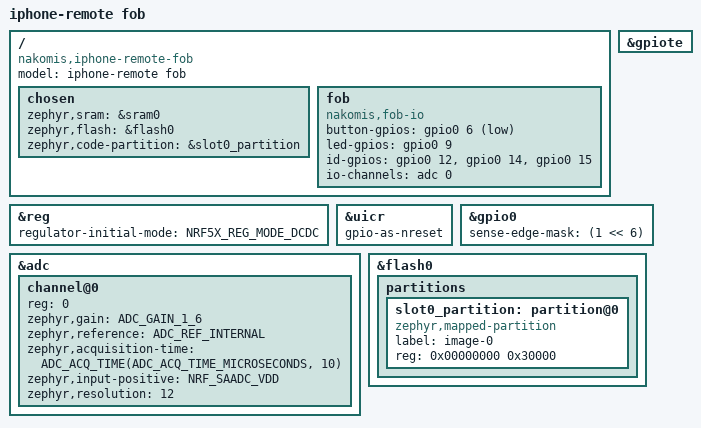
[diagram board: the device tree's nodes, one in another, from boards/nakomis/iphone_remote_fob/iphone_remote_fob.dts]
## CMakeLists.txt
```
cmake_minimum_required(VERSION 3.20.0)

# The fob's own board (boards/nakomis/iphone_remote_fob) and devicetree binding.
list(APPEND BOARD_ROOT ${CMAKE_CURRENT_SOURCE_DIR})
list(APPEND DTS_ROOT ${CMAKE_CURRENT_SOURCE_DIR})

find_package(Zephyr REQUIRED HINTS $ENV{ZEPHYR_BASE})
project(iphone_remote_fob)

target_sources(app PRIVATE src/main.c src/protocol.c)
```

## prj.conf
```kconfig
# Bluetooth: broadcaster (the press) and observer (the ack). No connections, no GATT.
CONFIG_BT=y
CONFIG_BT_BROADCASTER=y
CONFIG_BT_OBSERVER=y
CONFIG_BT_PERIPHERAL=n
CONFIG_BT_CENTRAL=n
CONFIG_BT_EXT_ADV=n
CONFIG_BT_DEVICE_NAME="iphone-remote"

CONFIG_GPIO=y
CONFIG_ADC=y
CONFIG_ENTROPY_GENERATOR=y

# Small: the nRF52810 has 192 KB flash and 24 KB RAM.
CONFIG_LOG=n
CONFIG_ASSERT=n
CONFIG_MAIN_STACK_SIZE=1536
CONFIG_SYSTEM_WORKQUEUE_STACK_SIZE=1024
CONFIG_SIZE_OPTIMIZATIONS=y
```

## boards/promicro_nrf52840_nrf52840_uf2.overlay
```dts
/* Development on the Pro Micro nRF52840 (UF2 bootloader: double-tap reset, copy
 * build/fob/zephyr/zephyr.uf2 to the drive). Wire a button from P0.17 to GND; the ID
 * jumpers are P0.20, P0.22 and P0.24 to GND (all open: fob 0). The LED is the board's own. */
#include <zephyr/dt-bindings/adc/nrf-saadc.h>

/ {
	fob {
		compatible = "nakomis,fob-io";
		button-gpios = <&gpio0 17 (GPIO_ACTIVE_LOW | GPIO_PULL_UP)>;
		led-gpios = <&gpio0 15 GPIO_ACTIVE_HIGH>;
		id-gpios = <&gpio0 20 0>, <&gpio0 22 0>, <&gpio0 24 0>;
		io-channels = <&adc 0>;
	};
};

&gpio0 {
	sense-edge-mask = <(1 << 17)>;
};

&adc {
	#address-cells = <1>;
	#size-cells = <0>;

	channel@0 {
		reg = <0>;
		zephyr,gain = "ADC_GAIN_1_6";
		zephyr,reference = "ADC_REF_INTERNAL";
		zephyr,acquisition-time = <ADC_ACQ_TIME(ADC_ACQ_TIME_MICROSECONDS, 10)>;
		zephyr,input-positive = <NRF_SAADC_VDD>;
		zephyr,resolution = <12>;
	};
};
```

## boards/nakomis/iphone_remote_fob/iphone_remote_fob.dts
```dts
/* The iphone-remote fob (hardware/fob, IREM-3/4): nRF52810-QCAA on a CR2032, DC/DC on,
 * no 32 kHz crystal. Pins from hardware/fob/board/fob_board.py. */
/dts-v1/;
#include <nordic/nrf52810_qfaa.dtsi>
#include <zephyr/dt-bindings/adc/nrf-saadc.h>

/ {
	model = "iphone-remote fob";
	compatible = "nakomis,iphone-remote-fob";

	chosen {
		zephyr,sram = &sram0;
		zephyr,flash = &flash0;
		zephyr,code-partition = &slot0_partition;
	};

	/* What the application drives (src/main.c). */
	fob {
		compatible = "nakomis,fob-io";
		/* SW1 to GND, with R2, an external 1 M pull-up. */
		button-gpios = <&gpio0 6 GPIO_ACTIVE_LOW>;
		/* D1, red, high-active through R1 (470 R). */
		led-gpios = <&gpio0 9 GPIO_ACTIVE_HIGH>;
		/* JP1..JP3 to GND: bit 0, 1, 2. The internal pull-ups are on only while they're read. */
		id-gpios = <&gpio0 12 0>, <&gpio0 14 0>, <&gpio0 15 0>;
		io-channels = <&adc 0>;
	};
};

&reg {
	regulator-initial-mode = <NRF5X_REG_MODE_DCDC>;
};

&uicr {
	gpio-as-nreset;
};

&gpiote {
	status = "okay";
};

/* The button wakes the chip with the port's SENSE, not a GPIOTE IN channel (which costs
 * current while waiting). */
&gpio0 {
	status = "okay";
	sense-edge-mask = <(1 << 6)>;
};

&adc {
	status = "okay";
	#address-cells = <1>;
	#size-cells = <0>;

	/* VDD, the cell, through the SAADC's own divider. */
	channel@0 {
		reg = <0>;
		zephyr,gain = "ADC_GAIN_1_6";
		zephyr,reference = "ADC_REF_INTERNAL";
		zephyr,acquisition-time = <ADC_ACQ_TIME(ADC_ACQ_TIME_MICROSECONDS, 10)>;
		zephyr,input-positive = <NRF_SAADC_VDD>;
		zephyr,resolution = <12>;
	};
};

&flash0 {
	partitions {
		ranges;
		#address-cells = <1>;
		#size-cells = <1>;

		/* No bootloader: the whole 192 KB is the application, flashed over SWD. */
		slot0_partition: partition@0 {
			compatible = "zephyr,mapped-partition";
			label = "image-0";
			reg = <0x00000000 0x30000>;
		};
	};
};
```

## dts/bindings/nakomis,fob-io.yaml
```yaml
description: The iphone-remote fob's button, LED, ID jumpers and VDD channel.

compatible: "nakomis,fob-io"

properties:
  button-gpios:
    type: phandle-array
    required: true
    description: The press button, active low.
  led-gpios:
    type: phandle-array
    required: true
    description: The ack LED.
  id-gpios:
    type: phandle-array
    required: true
    description: The three fob-ID jumpers to GND, bit 0 first. Read with the internal pull-ups.
  io-channels:
    type: phandle-array
    required: true
    description: The ADC channel that measures VDD.
```

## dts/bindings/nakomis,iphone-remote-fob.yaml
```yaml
description: The iphone-remote fob's button, LED, ID jumpers and VDD channel.

compatible: "nakomis,iphone-remote-fob"

properties:
  button-gpios:
    type: phandle-array
    required: true
    description: The press button, active low.
  led-gpios:
    type: phandle-array
    required: true
    description: The ack LED.
  id-gpios:
    type: phandle-array
    required: true
    description: The three fob-ID jumpers to GND, bit 0 first. Read with the internal pull-ups.
  io-channels:
    type: phandle-array
    required: true
    description: The ADC channel that measures VDD.
```

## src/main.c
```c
/* iphone-remote fob firmware (IREM-6): one press, one advert burst, one ack.
 *
 * Idle: System ON sleep, waiting on the button's SENSE. A press reads the fob ID and VDD,
 * advertises the press for up to 300 ms and scans for the phone's ack for up to 2 s. A matching
 * ack stops both and flashes the LED once; no ack gives two short flashes. Protocol:
 * docs/protocol.md (IREM-2); behaviour: the design doc's §7. */
#include <zephyr/bluetooth/bluetooth.h>
#include <zephyr/bluetooth/gap.h>
#include <zephyr/drivers/adc.h>
#include <zephyr/drivers/gpio.h>
#include <zephyr/kernel.h>
#include <zephyr/random/random.h>
#include <zephyr/sys/atomic.h>
#include <zephyr/sys/util.h>

#include "protocol.h"

#define FOB_NODE DT_PATH(fob)

/* Timing, docs/protocol.md §5. */
#define ADV_INTERVAL 0x20		/* 20 ms, in 0.625 ms units */
#define SCAN_INTERVAL 0x60		/* 60 ms */
#define SCAN_WINDOW 0x30		/* 30 ms: 50% duty */
#define BURST_MS 300
#define LISTEN_MS 2000
#define LISTEN_LOW_MS 1000		/* a tired cell listens for less... */
#define LOW_MV 2200			/* ...below this, and skips the LED */
#define RELEASE_MS 30			/* the button counts as released after this long quiet */
#define ACK_FLASH_MS 50
#define MISS_FLASH_MS 15
#define MISS_GAP_MS 120
#define FAULT_FLASH_MS 100		/* the radio refused to start: three of these */

static const struct gpio_dt_spec button = GPIO_DT_SPEC_GET(FOB_NODE, button_gpios);
static const struct gpio_dt_spec led = GPIO_DT_SPEC_GET(FOB_NODE, led_gpios);
static const struct gpio_dt_spec id_pins[3] = {
	GPIO_DT_SPEC_GET_BY_IDX(FOB_NODE, id_gpios, 0),
	GPIO_DT_SPEC_GET_BY_IDX(FOB_NODE, id_gpios, 1),
	GPIO_DT_SPEC_GET_BY_IDX(FOB_NODE, id_gpios, 2),
};
static const struct adc_dt_spec vdd_channel = ADC_DT_SPEC_GET(FOB_NODE);

/* Everything below runs on this queue, so the press state needs no lock; the scan callback
 * (the Bluetooth RX thread) only reads it to match an ack, then hands over to the queue. */
K_THREAD_STACK_DEFINE(fob_stack, 1536);
static struct k_work_q fob_q;

static struct {
	uint16_t counter;
	uint8_t fob_id;
	bool low;
} press;
/* Set while a press is waiting for its ack (the value of press.counter, plus 1, so 0 = none). */
static atomic_t listening_for;
/* The listening_for value an ack was matched against, so a late ack for an earlier press can't
 * end a newer one. */
static atomic_t acked_for;

/* The button is down. Set by the edge ISR, cleared by release_timer (also interrupt context), so
 * nothing on the work queue can hold up a release. */
static volatile bool held;

static uint8_t mfg[FOB_MFG_LEN];
static const struct bt_data ad[] = {
	BT_DATA(BT_DATA_UUID128_ALL, fob_press_uuid, 16),
	BT_DATA(BT_DATA_MANUFACTURER_DATA, mfg, sizeof(mfg)),
};

static void press_work_fn(struct k_work *w);
static void burst_end_fn(struct k_work *w);
static void listen_end_fn(struct k_work *w);
static void acked_fn(struct k_work *w);
static void led_step_fn(struct k_work *w);
static void release_fn(struct k_timer *t);
static K_WORK_DEFINE(press_work, press_work_fn);
static K_WORK_DEFINE(acked_work, acked_fn);
static K_WORK_DELAYABLE_DEFINE(burst_end, burst_end_fn);
static K_WORK_DELAYABLE_DEFINE(listen_end, listen_end_fn);
static K_WORK_DELAYABLE_DEFINE(led_step, led_step_fn);
static K_TIMER_DEFINE(release_timer, release_fn, NULL);

static uint8_t read_fob_id(void)
{
	int v[3];

	for (int i = 0; i < 3; i++) {
		gpio_pin_configure_dt(&id_pins[i], GPIO_INPUT | GPIO_PULL_UP);
	}
	k_busy_wait(20);
	for (int i = 0; i < 3; i++) {
		v[i] = gpio_pin_get_raw(id_pins[i].port, id_pins[i].pin);
		gpio_pin_configure_dt(&id_pins[i], GPIO_DISCONNECTED);
	}
	return fob_id_from_pins(v[0], v[1], v[2]);
}

/* VDD in mV, or 0 if it couldn't be read. */
static int read_vdd_mv(void)
{
	int16_t raw;
	struct adc_sequence seq = {.buffer = &raw, .buffer_size = sizeof(raw)};

	if (adc_sequence_init_dt(&vdd_channel, &seq) || adc_read_dt(&vdd_channel, &seq)) {
		return 0;
	}
	int32_t mv = raw;

	return adc_raw_to_millivolts_dt(&vdd_channel, &mv) ? 0 : mv;
}

/* LED flashes run on the system work queue, without blocking, so a flash never delays a press.
 * A new pattern replaces one still running. */
static struct {
	int steps;	/* LED changes still to make: on, off, on, off... */
	int on_ms, gap_ms;
} blink;

static void led_step_fn(struct k_work *w)
{
	if (blink.steps <= 0) {
		gpio_pin_set_dt(&led, 0);
		return;
	}
	bool on = blink.steps % 2 == 0;

	gpio_pin_set_dt(&led, on);
	blink.steps--;
	k_work_reschedule(&led_step, K_MSEC(on ? blink.on_ms : blink.gap_ms));
}

static void flash(int times, int on_ms, int gap_ms)
{
	k_work_cancel_delayable(&led_step);
	blink.steps = times * 2;
	blink.on_ms = on_ms;
	blink.gap_ms = gap_ms;
	k_work_reschedule(&led_step, K_NO_WAIT);
}

static void stop_radio(void)
{
	bt_le_adv_stop();
	bt_le_scan_stop();
}

static bool ad_has_ack(struct bt_data *data, void *user)
{
	bool *found = user;

	if ((data->type == BT_DATA_UUID128_ALL || data->type == BT_DATA_UUID128_SOME) &&
	    fob_list_has_ack(data->data, data->data_len, press.fob_id, press.counter)) {
		*found = true;
		return false;
	}
	return true;
}

static void scanned(const bt_addr_le_t *addr, int8_t rssi, uint8_t type, struct net_buf_simple *buf)
{
	bool found = false;
	atomic_val_t want = atomic_get(&listening_for);

	if (want == 0 || want != press.counter + 1) {
		return;
	}
	bt_data_parse(buf, ad_has_ack, &found);
	if (found) {
		atomic_set(&acked_for, want);
		k_work_submit_to_queue(&fob_q, &acked_work);
	}
}

static void press_work_fn(struct k_work *w)
{
	/* Stop a press still listening (a re-press within 2 s) before measuring, so VDD is read
	 * without the radio's load on the cell. */
	atomic_set(&listening_for, 0);
	stop_radio();
	k_msleep(2);
	int mv = read_vdd_mv();

	press.counter++;
	press.fob_id = read_fob_id();
	press.low = mv > 0 && mv < LOW_MV;
	fob_press_mfg(mfg, press.fob_id, press.counter, fob_battery_byte(mv));
	atomic_set(&listening_for, press.counter + 1);

	/* Non-connectable, from the chip's random static address (docs/protocol.md §2). */
	static const struct bt_le_adv_param adv =
		BT_LE_ADV_PARAM_INIT(BT_LE_ADV_OPT_USE_IDENTITY, ADV_INTERVAL, ADV_INTERVAL, NULL);
	static const struct bt_le_scan_param scan = {
		.type = BT_LE_SCAN_TYPE_PASSIVE,
		.interval = SCAN_INTERVAL,
		.window = SCAN_WINDOW,
	};

	if (bt_le_adv_start(&adv, ad, ARRAY_SIZE(ad), NULL, 0) || bt_le_scan_start(&scan, scanned)) {
		/* Not the same as "the phone didn't hear": three long flashes. */
		atomic_set(&listening_for, 0);
		stop_radio();
		flash(3, FAULT_FLASH_MS, FAULT_FLASH_MS);
		return;
	}
	k_work_reschedule_for_queue(&fob_q, &burst_end, K_MSEC(BURST_MS));
	k_work_reschedule_for_queue(&fob_q, &listen_end, K_MSEC(press.low ? LISTEN_LOW_MS : LISTEN_MS));
}

static void burst_end_fn(struct k_work *w)
{
	bt_le_adv_stop();
}

static void listen_end_fn(struct k_work *w)
{
	if (atomic_set(&listening_for, 0) == 0) {
		return;
	}
	stop_radio();
	if (!press.low) {
		flash(2, MISS_FLASH_MS, MISS_GAP_MS);	/* "the phone didn't hear" */
	}
}

static void acked_fn(struct k_work *w)
{
	if (!atomic_cas(&listening_for, atomic_get(&acked_for), 0)) {
		return;	/* a second ack advert for the same press, or one for an earlier press */
	}
	stop_radio();
	k_work_cancel_delayable(&burst_end);
	k_work_cancel_delayable(&listen_end);
	if (!press.low) {
		flash(1, ACK_FLASH_MS, 0);
	}
}

/* The first edge of a press acts at once; the release counts once the pin has been quiet and
 * high for RELEASE_MS, so contact bounce on either edge never makes a second press. Both run in
 * interrupt context at the same priority, so neither interrupts the other. */
static void release_fn(struct k_timer *t)
{
	if (gpio_pin_get_dt(&button) == 0) {
		held = false;
	}
}

static void button_edge(const struct device *dev, struct gpio_callback *cb, uint32_t pins)
{
	if (!held && gpio_pin_get_dt(&button) == 1) {
		held = true;
		k_work_submit_to_queue(&fob_q, &press_work);
	}
	k_timer_start(&release_timer, K_MSEC(RELEASE_MS), K_NO_WAIT);
}

static struct gpio_callback button_cb;

int main(void)
{
	k_work_queue_start(&fob_q, fob_stack, K_THREAD_STACK_SIZEOF(fob_stack), K_PRIO_PREEMPT(5), NULL);

	gpio_pin_configure_dt(&led, GPIO_OUTPUT_INACTIVE);
	for (int i = 0; i < 3; i++) {
		gpio_pin_configure_dt(&id_pins[i], GPIO_DISCONNECTED);
	}
	adc_channel_setup_dt(&vdd_channel);

	if (bt_enable(NULL)) {
		flash(5, 200, 200);	/* can't start the radio: nothing else will work */
		return 0;
	}
	/* A fresh cell must not repeat the counter the phone saw last (docs/protocol.md §2). */
	sys_rand_get(&press.counter, sizeof(press.counter));

	gpio_pin_configure_dt(&button, GPIO_INPUT);
	gpio_init_callback(&button_cb, button_edge, BIT(button.pin));
	gpio_add_callback_dt(&button, &button_cb);
	gpio_pin_interrupt_configure_dt(&button, GPIO_INT_EDGE_BOTH);

	flash(1, 20, 0);	/* alive */
	return 0;
}
```

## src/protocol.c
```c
#include "protocol.h"

#include <string.h>

/* 3B89DBAA-2669-4548-9D04-6876798D0903, reversed. */
const uint8_t fob_press_uuid[16] = {
	0x03, 0x09, 0x8D, 0x79, 0x76, 0x68, 0x04, 0x9D,
	0x48, 0x45, 0x69, 0x26, 0xAA, 0xDB, 0x89, 0x3B,
};

/* The ack prefix 6FDAD356-8165-4FDB-A4F2-B25C2B, reversed: on-air bytes 3..15. */
static const uint8_t ack_prefix_on_air[13] = {
	0x2B, 0x5C, 0xB2, 0xF2, 0xA4, 0xDB, 0x4F, 0x65, 0x81, 0x56, 0xD3, 0xDA, 0x6F,
};

uint8_t fob_battery_byte(int vdd_mv)
{
	if (vdd_mv <= 0) {
		return 0;
	}
	int units = (vdd_mv + 10) / 20;

	return units < 1 ? 1 : units > 255 ? 255 : (uint8_t)units;
}

void fob_press_mfg(uint8_t out[FOB_MFG_LEN], uint8_t fob_id, uint16_t counter, uint8_t battery)
{
	out[0] = FOB_COMPANY_ID & 0xFF;
	out[1] = FOB_COMPANY_ID >> 8;
	out[2] = FOB_PROTOCOL_VERSION;
	out[3] = fob_id;
	out[4] = counter & 0xFF;
	out[5] = counter >> 8;
	out[6] = battery;
}

bool fob_is_ack(const uint8_t *uuid, size_t len, uint8_t fob_id, uint16_t counter)
{
	return len == 16 && uuid[0] == (counter & 0xFF) && uuid[1] == (counter >> 8) &&
	       uuid[2] == fob_id && memcmp(&uuid[3], ack_prefix_on_air, sizeof(ack_prefix_on_air)) == 0;
}

bool fob_list_has_ack(const uint8_t *data, size_t len, uint8_t fob_id, uint16_t counter)
{
	for (size_t i = 0; i + 16 <= len; i += 16) {
		if (fob_is_ack(&data[i], 16, fob_id, counter)) {
			return true;
		}
	}
	return false;
}

uint8_t fob_id_from_pins(int bit0, int bit1, int bit2)
{
	return (uint8_t)((bit0 ? 0 : 1) | (bit1 ? 0 : 2) | (bit2 ? 0 : 4));
}
```

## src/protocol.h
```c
/* The iphone-remote over-the-air protocol, version 1 (docs/protocol.md, IREM-2).
 * Pure functions, no Zephyr: unit tested on the host (tests/). */
#pragma once

#include <stdbool.h>
#include <stddef.h>
#include <stdint.h>

#define FOB_PROTOCOL_VERSION 0x01
#define FOB_COMPANY_ID 0xFFFF
#define FOB_MAX_ID 7

/* Manufacturer data: company ID (2, little-endian) + version, fob_id, counter (2), battery. */
#define FOB_MFG_LEN 7

/* The press UUID 3B89DBAA-2669-4548-9D04-6876798D0903, on-air order (least significant first). */
extern const uint8_t fob_press_uuid[16];

/* Battery byte: VDD in 20 mV units, 0 = not measured, clamped to 1..255. */
uint8_t fob_battery_byte(int vdd_mv);

/* Fills out[FOB_MFG_LEN] with the manufacturer data of a press. */
void fob_press_mfg(uint8_t out[FOB_MFG_LEN], uint8_t fob_id, uint16_t counter, uint8_t battery);

/* Whether a 128-bit UUID as received on air (16 bytes, least significant first) is the ack
 * for (fob_id, counter). */
bool fob_is_ack(const uint8_t *uuid, size_t len, uint8_t fob_id, uint16_t counter);

/* Whether any 128-bit UUID in a list AD's data (len a multiple of 16) is that ack. */
bool fob_list_has_ack(const uint8_t *data, size_t len, uint8_t fob_id, uint16_t counter);

/* The fob ID from the three jumper pins as read (1 = high = open); closed (low) is a 1 bit. */
uint8_t fob_id_from_pins(int bit0, int bit1, int bit2);
```
